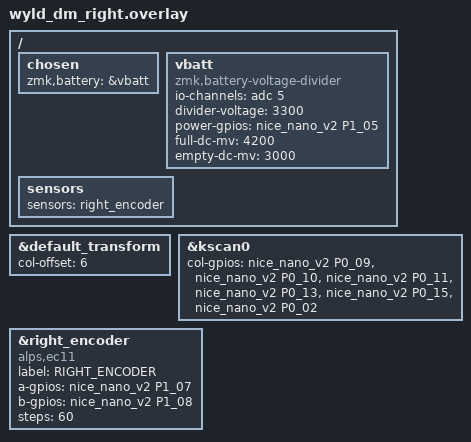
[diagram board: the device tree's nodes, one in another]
#include "wyld_dm_common.dtsi"

/ {
    chosen {
        zmk,battery = &vbatt;
    };
    
    vbatt: vbatt {
        compatible = "zmk,battery-voltage-divider";
        io-channels = <&adc 5>;
        divider-voltage = <3300>;
        power-gpios = <&nice_nano_v2 P1_05 GPIO_ACTIVE_HIGH>;
        full-dc-mv = <4200>;
        empty-dc-mv = <3000>;
    };

    sensors {
        sensors = <&right_encoder>;
    };
};

&default_transform {
    col-offset = <6>;
};

&kscan0 {
    col-gpios
        = <&nice_nano_v2 P0_09 GPIO_ACTIVE_HIGH>
        , <&nice_nano_v2 P0_10 GPIO_ACTIVE_HIGH>
        , <&nice_nano_v2 P0_11 GPIO_ACTIVE_HIGH>
        , <&nice_nano_v2 P0_13 GPIO_ACTIVE_HIGH>
        , <&nice_nano_v2 P0_15 GPIO_ACTIVE_HIGH>
        , <&nice_nano_v2 P0_02 GPIO_ACTIVE_HIGH>
        ;
};

&right_encoder {
    compatible = "alps,ec11";
    label = "RIGHT_ENCODER";
    a-gpios = <&nice_nano_v2 P1_07 (GPIO_ACTIVE_HIGH | GPIO_PULL_UP)>;
    b-gpios = <&nice_nano_v2 P1_08 (GPIO_ACTIVE_HIGH | GPIO_PULL_UP)>;
    steps = <60>;
    status = "okay";
};
